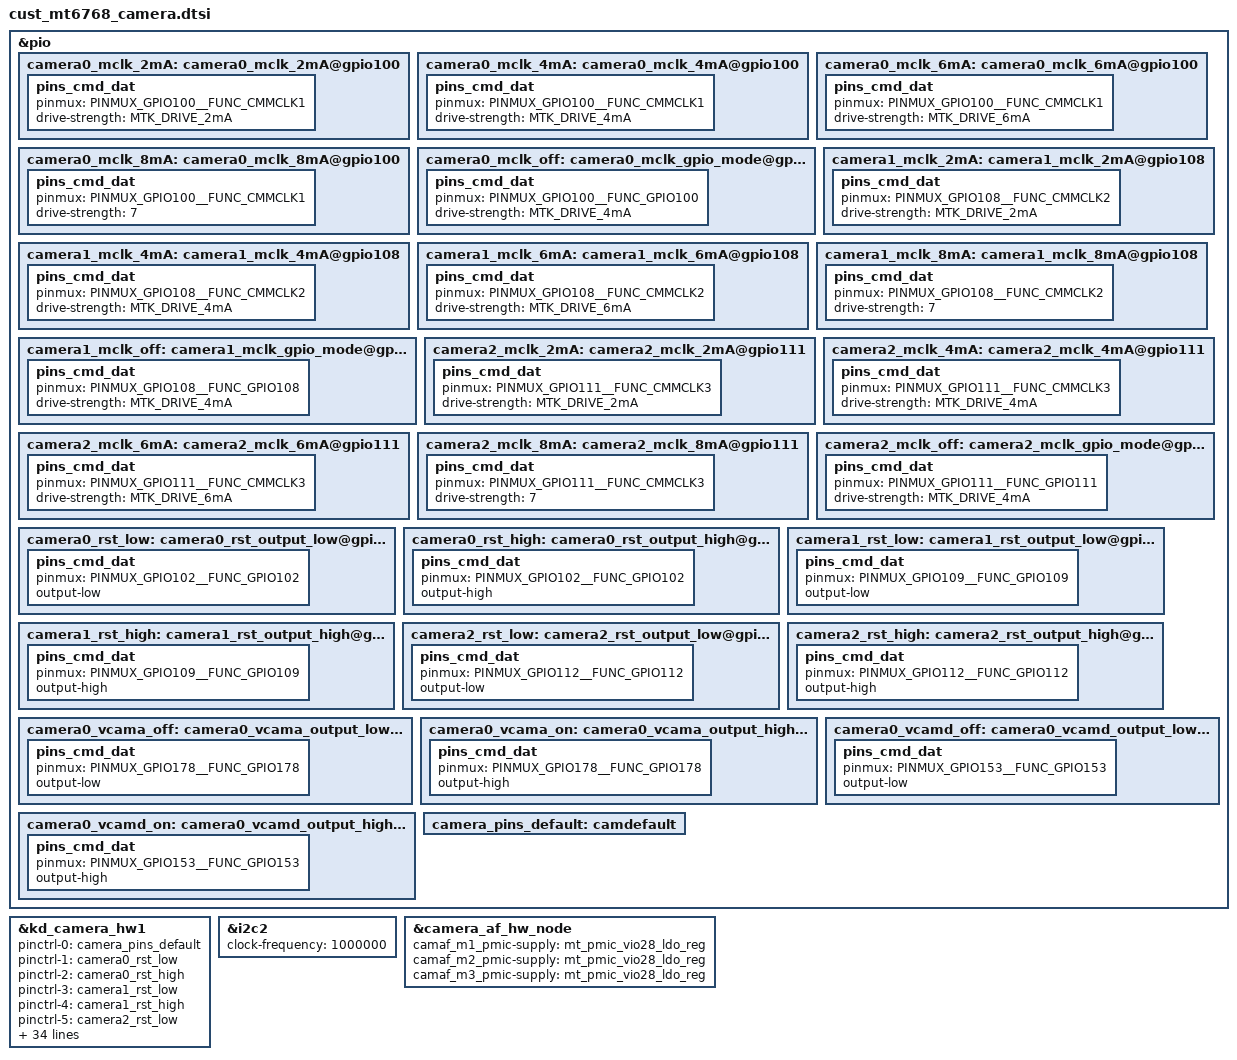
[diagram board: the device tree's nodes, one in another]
// SPDX-License-Identifier: (GPL-2.0 OR MIT)
/*
 * Copyright (c) 2019 MediaTek Inc.
 */
/* CAMERA GPIO standardization */
&pio {
	camera0_mclk_2mA: camera0_mclk_2mA@gpio100 {
		pins_cmd_dat {
			pinmux = <PINMUX_GPIO100__FUNC_CMMCLK1>;
			drive-strength = <MTK_DRIVE_2mA>;
		};
	};
	camera0_mclk_4mA: camera0_mclk_4mA@gpio100 {
		pins_cmd_dat {
			pinmux = <PINMUX_GPIO100__FUNC_CMMCLK1>;
			drive-strength = <MTK_DRIVE_4mA>;
		};
	};
	camera0_mclk_6mA: camera0_mclk_6mA@gpio100 {
		pins_cmd_dat {
			pinmux = <PINMUX_GPIO100__FUNC_CMMCLK1>;
			drive-strength = <MTK_DRIVE_6mA>;
		};
	};
	camera0_mclk_8mA: camera0_mclk_8mA@gpio100 {
		pins_cmd_dat {
			pinmux = <PINMUX_GPIO100__FUNC_CMMCLK1>;
			drive-strength = <7>;
		};
	};
	camera0_mclk_off: camera0_mclk_gpio_mode@gpio100 {
		pins_cmd_dat {
			pinmux = <PINMUX_GPIO100__FUNC_GPIO100>;
			drive-strength = <MTK_DRIVE_4mA>;
		};
	};
	camera1_mclk_2mA: camera1_mclk_2mA@gpio108 {
		pins_cmd_dat {
			pinmux = <PINMUX_GPIO108__FUNC_CMMCLK2>;
			drive-strength = <MTK_DRIVE_2mA>;
		};
	};
	camera1_mclk_4mA: camera1_mclk_4mA@gpio108 {
		pins_cmd_dat {
			pinmux = <PINMUX_GPIO108__FUNC_CMMCLK2>;
			drive-strength = <MTK_DRIVE_4mA>;
		};
	};
	camera1_mclk_6mA: camera1_mclk_6mA@gpio108 {
		pins_cmd_dat {
			pinmux = <PINMUX_GPIO108__FUNC_CMMCLK2>;
			drive-strength = <MTK_DRIVE_6mA>;
		};
	};
	camera1_mclk_8mA: camera1_mclk_8mA@gpio108 {
		pins_cmd_dat {
			pinmux = <PINMUX_GPIO108__FUNC_CMMCLK2>;
			drive-strength = <7>;
		};
	};
	camera1_mclk_off: camera1_mclk_gpio_mode@gpio108 {
		pins_cmd_dat {
			pinmux = <PINMUX_GPIO108__FUNC_GPIO108>;
			drive-strength = <MTK_DRIVE_4mA>;
		};
	};
	camera2_mclk_2mA: camera2_mclk_2mA@gpio111 {
		pins_cmd_dat {
			pinmux = <PINMUX_GPIO111__FUNC_CMMCLK3>;
			drive-strength = <MTK_DRIVE_2mA>;
		};
	};
	camera2_mclk_4mA: camera2_mclk_4mA@gpio111 {
		pins_cmd_dat {
			pinmux = <PINMUX_GPIO111__FUNC_CMMCLK3>;
			drive-strength = <MTK_DRIVE_4mA>;
		};
	};
	camera2_mclk_6mA: camera2_mclk_6mA@gpio111 {
		pins_cmd_dat {
			pinmux = <PINMUX_GPIO111__FUNC_CMMCLK3>;
			drive-strength = <MTK_DRIVE_6mA>;
		};
	};
	camera2_mclk_8mA: camera2_mclk_8mA@gpio111 {
		pins_cmd_dat {
			pinmux = <PINMUX_GPIO111__FUNC_CMMCLK3>;
			drive-strength = <7>;
		};
	};
	camera2_mclk_off: camera2_mclk_gpio_mode@gpio111 {
		pins_cmd_dat {
			pinmux = <PINMUX_GPIO111__FUNC_GPIO111>;
			drive-strength = <MTK_DRIVE_4mA>;
		};
	};
	camera0_rst_low: camera0_rst_output_low@gpio102 {
		pins_cmd_dat {
			pinmux = <PINMUX_GPIO102__FUNC_GPIO102>;
			output-low;
		};
	};
	camera0_rst_high: camera0_rst_output_high@gpio102 {
		pins_cmd_dat {
			pinmux = <PINMUX_GPIO102__FUNC_GPIO102>;
			output-high;
		};
	};
	camera1_rst_low: camera1_rst_output_low@gpio109 {
		pins_cmd_dat {
			pinmux = <PINMUX_GPIO109__FUNC_GPIO109>;
			output-low;
		};
	};
	camera1_rst_high: camera1_rst_output_high@gpio109 {
		pins_cmd_dat {
			pinmux = <PINMUX_GPIO109__FUNC_GPIO109>;
			output-high;
		};
	};

	camera2_rst_low: camera2_rst_output_low@gpio112 {
		pins_cmd_dat {
			pinmux = <PINMUX_GPIO112__FUNC_GPIO112>;
			output-low;
		};
	};
	camera2_rst_high: camera2_rst_output_high@gpio112 {
		pins_cmd_dat {
			pinmux = <PINMUX_GPIO112__FUNC_GPIO112>;
			output-high;
		};
	};

	camera0_vcama_off: camera0_vcama_output_low@gpio178 {
		pins_cmd_dat {
			pinmux = <PINMUX_GPIO178__FUNC_GPIO178>;
			output-low;
		};
	};
	camera0_vcama_on: camera0_vcama_output_high@gpio178 {
		pins_cmd_dat {
			pinmux = <PINMUX_GPIO178__FUNC_GPIO178>;
			output-high;
		};
	};
	camera0_vcamd_off: camera0_vcamd_output_low@gpio153 {
		pins_cmd_dat {
			pinmux = <PINMUX_GPIO153__FUNC_GPIO153>;
			output-low;
		};
	};
	camera0_vcamd_on: camera0_vcamd_output_high@gpio153 {
		pins_cmd_dat {
			pinmux = <PINMUX_GPIO153__FUNC_GPIO153>;
			output-high;
		};
	};
	camera_pins_default: camdefault {
	};

};

&kd_camera_hw1 {
	pinctrl-names = "default",
			"cam0_rst0", "cam0_rst1",
			"cam1_rst0", "cam1_rst1",
			"cam2_rst0", "cam2_rst1",
			"cam0_vcama_on",
			"cam0_vcama_off",
			"cam0_vcamd_on",
			"cam0_vcamd_off",
			"cam0_mclk_off",
			"cam0_mclk_2mA", "cam0_mclk_4mA",
			"cam0_mclk_6mA", "cam0_mclk_8mA",
			"cam1_mclk_off",
			"cam1_mclk_2mA", "cam1_mclk_4mA",
			"cam1_mclk_6mA", "cam1_mclk_8mA",
			"cam2_mclk_off",
			"cam2_mclk_2mA", "cam2_mclk_4mA",
			"cam2_mclk_6mA", "cam2_mclk_8mA";

	pinctrl-0 = <&camera_pins_default>;
	pinctrl-1 = <&camera0_rst_low>;
	pinctrl-2 = <&camera0_rst_high>;
	pinctrl-3 = <&camera1_rst_low>;
	pinctrl-4 = <&camera1_rst_high>;
	pinctrl-5 = <&camera2_rst_low>;
	pinctrl-6 = <&camera2_rst_high>;
	pinctrl-7 = <&camera0_vcama_on>;
	pinctrl-8 = <&camera0_vcama_off>;
	pinctrl-9 = <&camera0_vcamd_on>;
	pinctrl-10 = <&camera0_vcamd_off>;
	pinctrl-11 = <&camera0_mclk_off>;
	pinctrl-12 = <&camera0_mclk_2mA>;
	pinctrl-13 = <&camera0_mclk_4mA>;
	pinctrl-14 = <&camera0_mclk_6mA>;
	pinctrl-15 = <&camera0_mclk_8mA>;
	pinctrl-16 = <&camera1_mclk_off>;
	pinctrl-17 = <&camera1_mclk_2mA>;
	pinctrl-18 = <&camera1_mclk_4mA>;
	pinctrl-19 = <&camera1_mclk_6mA>;
	pinctrl-20 = <&camera1_mclk_8mA>;
	pinctrl-21 = <&camera2_mclk_off>;
	pinctrl-22 = <&camera2_mclk_2mA>;
	pinctrl-23 = <&camera2_mclk_4mA>;
	pinctrl-24 = <&camera2_mclk_6mA>;
	pinctrl-25 = <&camera2_mclk_8mA>;

	cam1_vcama-supply = <&mt_pmic_vcama2_ldo_reg>;
	cam1_vcamd-supply = <&mt_pmic_vcamd_ldo_reg>;
	cam2_vcama-supply = <&mt_pmic_vcama2_ldo_reg>;
	/* N19A code for HQ-365583 by p-xuyechen at 2024/1/11 */
	cam2_vcamd-supply = <&mt_pmic_vcamd_ldo_reg>;

	cam0_vcamio-supply = <&mt_pmic_vcamio_ldo_reg>;
	cam1_vcamio-supply = <&mt_pmic_vcamio_ldo_reg>;
	cam2_vcamio-supply = <&mt_pmic_vcamio_ldo_reg>;

	cam0_vcamaf-supply = <&mt_pmic_vio28_ldo_reg>;

	cam0_enable_sensor = "s5khm6_sunny_main_mipi_raw s5khm6_aac_main_mipi_raw s5khm6_truly_main_mipi_raw";
	/* N19A code for HQ-360492 by p-xuyechen at 2023/12/20 */
	cam1_enable_sensor = "ov13b10_sunny_front_mipi_raw ov13b10_ofilm_front_mipi_raw s5k3l6_aac_front_mipi_raw";
	/* N19A code for HQ-357416 by p-xuyechen at 2023/12/17 */
	cam2_enable_sensor = "gc02m1_sunny_macro_mipi_raw gc02m1_truly_macro_mipi_raw gc02m1_aac_macro_mipi_raw";

	status = "okay";

};
/* CAMERA GPIO end */

&i2c2 {
	status = "okay";
	clock-frequency = <1000000>;
	#address-cells = <1>;
	#size-cells = <0>;
};

/* CAMERA AF */
&camera_af_hw_node {
	camaf_m1_pmic-supply = <&mt_pmic_vio28_ldo_reg>;
	camaf_m2_pmic-supply = <&mt_pmic_vio28_ldo_reg>;
	camaf_m3_pmic-supply = <&mt_pmic_vio28_ldo_reg>;
	status = "okay";
};
/* CAMERA AF end */
